# tviibh16m register map
Vendor: Infineon Technologies; Series: TVIIBH16M; File version: 1.0
CPU: CM7 r0p1, little endian, MPU, FPU, double-precision FPU, I-cache, D-cache, VTOR, ITCM, DTCM, 3 interrupt priority bits, 16 interrupts
Registers are 32-bit, read-write, reset 0x0 unless marked. A register's access mark holds for its fields unless they carry their own. Offsets are from the block's base; [hi:lo] are bit positions; {n}, {i} and the like mark numbered series.

## ETH0 (part 2 of 3) — Ethernet Interface
Base 0x40480000
Same registers: ETH1 0x40490000
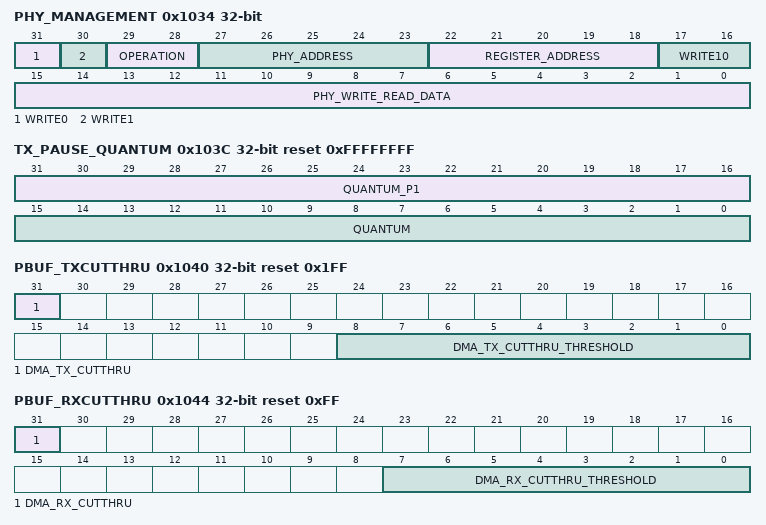
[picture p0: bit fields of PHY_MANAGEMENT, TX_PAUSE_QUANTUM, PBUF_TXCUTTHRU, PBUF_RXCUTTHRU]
0x1034 PHY_MANAGEMENT — The PHY maintenance register is implemented as a shift register. Writing to the register starts a shift operation which is signalled as complete when bit-2 is set in the network status register. It takes about 2000 pclk cycles to complete, when MDC is set for pclk divide by 32 in the network configuration register. An interrupt is generated upon completion. During this time, the MSB of the register is output on the MDIO pin and the LSB updated from the MDIO pin with each MDC cycle. This causes transmission of a PHY management frame on MDIO. See Section 22.2.4.5 of the IEEE 802.3 standard. Reading during the shift operation will return the current contents of the shift register. At the end of management operation, the bits will have shifted back to their original locations. For a read operation, the data bits will be updated with data read from the PHY. It is important to write the correct values to the register to ensure a valid PHY management frame is produced. The MDIO interface can read IEEE 802.3 clause 45 PHYs as well as clause 22 PHYs. To read clause 45 PHYs, bit 30 should be written with a 0 rather than a 1. For a description of MDC generation, see Network Configuration Register.
  [31] WRITE0 — Must be written with 0.
  [30] WRITE1 — Must be written to 1 for a valid Clause 22 frame and to 0 for a valid Clause 45 frame.
  [29:28] OPERATION — Operation. For a Clause 45 frame: 00 is an addr, 01 is a write, 10 is a post read increment, 11 is a read frame. For a Clause 22 frame: 10 is a read, 01 is a write.
  [27:23] PHY_ADDRESS
  [22:18] REGISTER_ADDRESS — Register address - specifies the register in the PHY to access.
  [17:16] WRITE10 — Must be written with 10.
  [15:0] PHY_WRITE_READ_DATA — For a write operation this is written with the data to be written to the PHY. After a read operation this contains the data read from the PHY.
0x1038 PAUSE_TIME ro — Received Pause Quantum Register
  [15:0] QUANTUM — Received pause quantum - stores the current value of the received pause quantum register which is decremented every 512 bit times.
0x103C TX_PAUSE_QUANTUM reset 0xFFFFFFFF — Transmit Pause Quantum Register
  [31:16] QUANTUM_P1 — Transmit pause quantum - written with the pause quantum value for pause frame transmission of priority 1.
  [15:0] QUANTUM — Transmit pause quantum - written with the pause quantum value for pause frame transmission.
0x1040 PBUF_TXCUTTHRU reset 0x1FF — Partial store and forward is only applicable when using the DMA configured in SRAM based packet buffer mode. It is also not available when using multi buffer frames. TX Partial Store and Forward
  [31] DMA_TX_CUTTHRU — Enable TX partial store and forward operation
  [8:0] DMA_TX_CUTTHRU_THRESHOLD — Watermark value. This value must be >= 0x9. The reset value depends on the value of the configuration option `gem_tx_pbuf_addr, which is defined in the verilog defs configuration file. The value chosen for the generation of the userguide was `gem_tx_pbuf_addr = 9
0x1044 PBUF_RXCUTTHRU reset 0xFF — RX Partial Store and Forward
  [31] DMA_RX_CUTTHRU — Enable RX partial store and forward operation
  [7:0] DMA_RX_CUTTHRU_THRESHOLD — Watermark value. The reset value depends on the value of the configuration option `gem_rx_pbuf_addr, which is defined in the verilog defs configuration file. The value chosen for the generation of the userguide was `gem_rx_pbuf_addr = 8.
0x1048 JUMBO_MAX_LENGTH reset 0x600 — Maximum Jumbo Frame Size.
  [13:0] JUMBO_MAX_LENGTH — Maximum Jumbo Frame Size - resets to the gem_jumbo_max_length define value.
0x104C EXTERNAL_FIFO_INTERFACE ro — Not presents.
  [31:0] REMOVED_31_0 — Write ignore, read 0
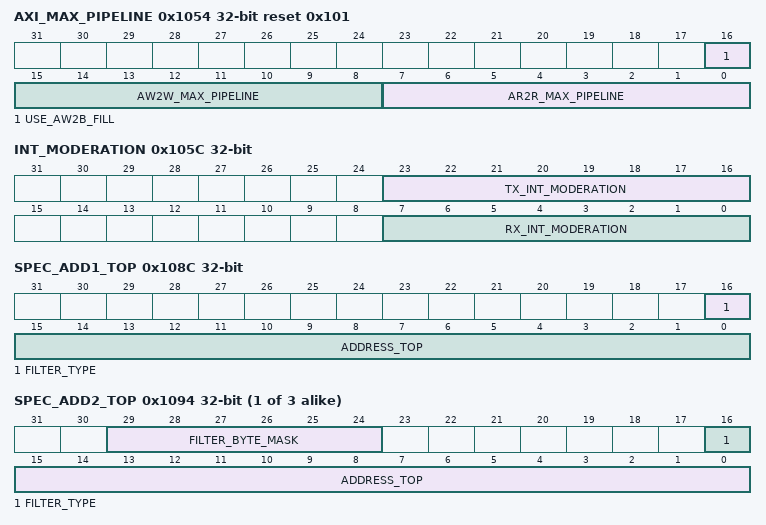
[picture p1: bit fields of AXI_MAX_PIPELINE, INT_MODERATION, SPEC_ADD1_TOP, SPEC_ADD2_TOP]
0x1054 AXI_MAX_PIPELINE reset 0x101 — Used to set the maximum amount of outstanding transactions on the AXI bus between AR / R channels and AW / W channels. Cannot be more than the depth of the configured AXI pipeline FIFO (defined in verilog defs.v)
  [16] USE_AW2B_FILL — For the write issuing capability as defined in bits 15:8 of this register, select whether the max number of transactions operates between the AW to W AXI channel or the AW to B channel. Set to 0 to operate between the AW and W channels. Set to 1 to operate between the AW and B channels.
  [15:8] AW2W_MAX_PIPELINE — Defines the maximum number of outstanding AXI write requests that can be issued by the DMA via the AW channel.
  [7:0] AR2R_MAX_PIPELINE — Defines the maximum number of outstanding AXI read requests that can be issued by the DMA via the AR channel.
0x1058 RSC_CONTROL ro — Not presents. Access to the register will return AHB error.
  [31:0] REMOVED_31_0 — Write ignore, read 0
0x105C INT_MODERATION — Used to moderate the number of transmit and receive complete interrupts issued. With interrupt moderation enabled receive and transmit interrupts are not generated immediately a frame is transmitted or received. Instead when a receive or transmit event occurs a timer is started and the interrupt is asserted after it times out. This limits the frequency with which the CPU receives interrupts. When interrupt moderation is enabled interrupt status bit one is always used for receive and bit 7 is always used for transmit even when priority queuing is enabled. With interrupt moderation 800ns periods are counted. GEM determines what constitutes an 800ns period by looking at the tbi (bit 11), gigabit bit (10) and speed (bit 0) bits in the network configuration register and counting tx_clk cycles. Bit 0 needs to be set to 1 for 100M operation.
  [23:16] TX_INT_MODERATION — Count of 800ns periods before bit 7 is set in the interrupt status register after a frame is transmitted. A non-zero value indicates transmit interrupt moderation will be performed.
  [7:0] RX_INT_MODERATION — Count of 800ns periods before bit 1 is set in the interrupt status register after a frame is received. A non-zero value indicates receive interrupt moderation will be performed.
0x1060 SYS_WAKE_TIME — Used to pause transmission after deassertion of tx_lpi_en. Each unit in this register corresponds to 64ns in gigabit mode, 320ns in 100M mode and 3200ns at 10M. After tx_lpi_en is deasserted transmission will pause for the set time.
  [15:0] SYS_WAKE_TIME — Count of 64ns, 320ns or 3200ns intervals before transmission starts after deassertion of tx_lpi_en (each interval is equivalent to eight tx_clk periods and so varies with data rate).
0x1080 HASH_BOTTOM — The unicast hash enable and the multicast hash enable bits in the network configuration register enable the reception of hash matched frames. Hash Register Bottom (31 to 0 bits)
  [31:0] ADDRESS_HASH_B — The first 32 bits of the hash address register.
0x1084 HASH_TOP — Hash Register Top (63 to 32 bits)
  [31:0] ADDRESS_HASH_T — The remaining 32 bits of the hash address register.
0x1088 SPEC_ADD1_BOTTOM — The addresses stored in the specific address registers are deactivated at reset or when their corresponding specific address register bottom is written. They are activated when specific address register top is written.
  [31:0] ADDRESS_ADD1_B — 'Least significant 32 bits of the destination address, that is bits 31:0. Bit zero indicates whether the address is multicast or unicast and corresponds to the least significant bit of the first byte received.'
0x108C SPEC_ADD1_TOP — Specific Address Top
  [16] FILTER_TYPE — This control bit selects whether this filter should be comparing the MAC source address or the MAC destination address of the received Ethernet frame. When set to zero, the filter is a destination address filter. When set to one, the filter is a source address filter. Specific address 1. The most significant bits of the destination address, that is bits 47:32.
  [15:0] ADDRESS_TOP — Specific address 1. The most significant bits of the destination/source address that is to be compared, that is bits 47:32.
{0x1080+8i} SPEC_ADD{i}_BOTTOM (i=2..4) — The addresses stored in the specific address registers are deactivated at reset or when their corresponding specific address register bottom is written. They are activated when specific address register top is written.
  [31:0] ADDRESS_BOTTOM — Least significant 32 bits of the destination address, that is bits 31:0. Bit zero indicates whether the address is multicast or unicast and corresponds to the least significant bit of the first byte received.
{0x1084+8i} SPEC_ADD{i}_TOP (i=2..4) — Specific Address Top
  [29:24] FILTER_BYTE_MASK — When high, the associated byte of the specific address will not be compared. Bit 24 controls whether the first byte received should be compared. Bit 29 controls whether the last byte received should be compared.
  [16] FILTER_TYPE — This control bit selects whether this filter should be comparing the MAC source address or the MAC destination address of the received Ethernet frame. When set to zero, the filter is a destination address filter. When set to one, the filter is a source address filter. Specific address 1. The most significant bits of the destination address, that is bits 47:32.
  [15:0] ADDRESS_TOP — Specific address 1. The most significant bits of the destination/source address that is to be compared, that is bits 47:32.
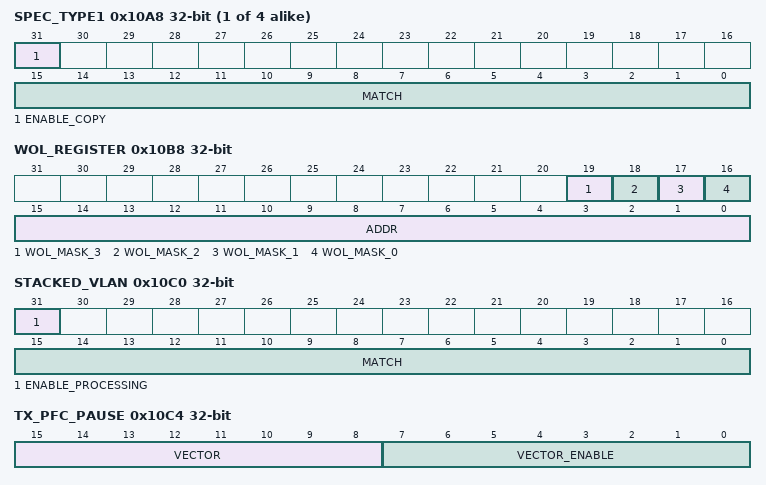
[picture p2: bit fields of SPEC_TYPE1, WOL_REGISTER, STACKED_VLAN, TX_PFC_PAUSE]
{0x10A4+4i} SPEC_TYPE{i} (i=1..4) — Type ID Match {i}
  [31] ENABLE_COPY — Enable copying of type ID match {i} matched frames.
  [15:0] MATCH — Type ID match {i}. For use in comparisons with received frames type ID/length field.
0x10B8 WOL_REGISTER — Wake on LAN Register. Presents in design, but feature is not supported.
  [19] WOL_MASK_3 — Wake on LAN multicast hash event enable. When set multicast hash events will cause the wol output to be asserted.
  [18] WOL_MASK_2 — Wake on LAN specific address register 1 event enable. When set specific address 1 events will cause the wol output to be asserted.
  [17] WOL_MASK_1 — Wake on LAN ARP request event enable. When set ARP request events will cause the wol output to be asserted.
  [16] WOL_MASK_0 — Wake on LAN magic packet event enable. When set magic packet events will cause the wol output to be asserted.
  [15:0] ADDR — Wake on LAN ARP request IP address. Written to define the least significant 16 bits of the target IP address that is matched to generate a Wake on LAN event. A value of zero will not generate an event, even if this is matched by the received frame.
0x10BC STRETCH_RATIO — IPG stretch register
  [15:0] IPG_STRETCH — IPG Stretch. Bits 7:0 are multiplied with the previously transmitted frame length (including preamble) bits 15:8 +1 divide the frame length. If the resulting number is greater than 96 and bit 28 is set in the network configuration register then the resulting number is used for the transmit inter-packet-gap. 1 is added to bits 15:8 to prevent a divide by zero.
0x10C0 STACKED_VLAN
  [31] ENABLE_PROCESSING — Enable stacked VLAN processing mode
  [15:0] MATCH — User defined VLAN_TYPE field. When Stacked VLAN is enabled, the first VLAN tag in a received frame will only be accepted if the VLAN type field is equal to this user defined VLAN_TYPE OR equal to the standard VLAN type (0x8100). Note that the second VLAN tag of a Stacked VLAN packet will only be matched correctly if its VLAN_TYPE field equals 0x8100.
0x10C4 TX_PFC_PAUSE — Transmit PFC Pause Register
  [15:8] VECTOR — Priority Vector Pause Size. If bit 17 of the network control register is written with a one then for each entry equal to zero in the Transmit PFC Pause Register[15:8], the PFC pause frame's pause quantum field associated with that entry will be taken from the transmit pause quantum register. For each entry equal to one in the Transmit PFC Pause Register [15:8], the pause quantum associated with that entry will be zero.
  [7:0] VECTOR_ENABLE — Priority Vector Enable. If bit 17 of the network control register is written with a one then the priority enable vector of the PFC priority based pause frame will be set equal to the value stored in this register [7:0].
0x10C8 MASK_ADD1_BOTTOM — Specific Address Mask 1 Bottom (31 to 0 bits)
  [31:0] ADDRESS_MASK_BOTTOM — Specific Address Mask. Setting a bit to one masks the corresponding bit in the specific address 1 register (31 to 0 bits)
0x10CC MASK_ADD1_TOP — Specific Address Mask 1 Top (47 to 32 bits)
  [15:0] ADDRESS_MASK_TOP — Specific Address Mask. Setting a bit to one masks the corresponding bit in the specific address 1 register (47 to 32 bits).
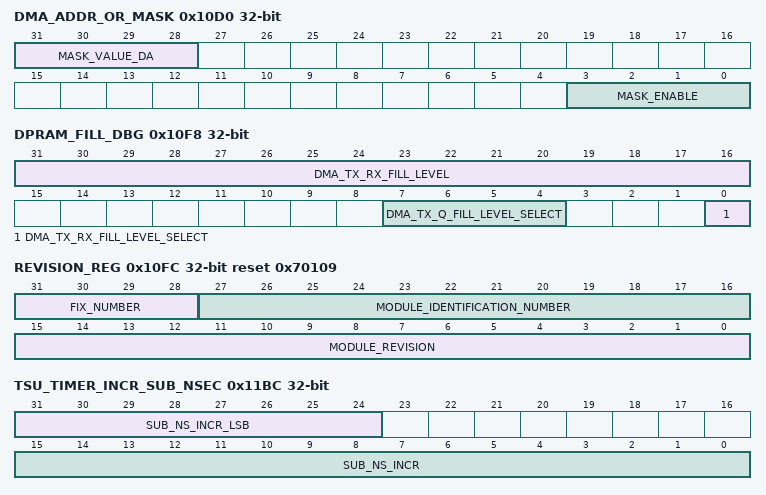
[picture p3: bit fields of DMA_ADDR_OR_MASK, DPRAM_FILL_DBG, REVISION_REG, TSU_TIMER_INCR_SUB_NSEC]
0x10D0 DMA_ADDR_OR_MASK — Receive DMA Data Buffer Address Mask
  [31:28] MASK_VALUE_DA — Data Buffer Address Mask Value. Values used to force bits 31:28 of the receive data buffer AHB address to a particular value when the associated enable bits stored in this register [3:0] are set. Any changes to this register will be ignored while the DMA is currently processing a receive packet. It will only affect the next full packet to be written to external system memory.
  [3:0] MASK_ENABLE — Data Buffer Address Mask Enable. These bits are associated directly with bits[31:28].When bit 0 is set, the AXI/AHB address bit 28 used for accessing the receive data buffers will be forced to the value stored in bit 28 of this register. When bit 1 is set, the AXI/AHB address bit 29 used for accessing the receive data buffers will be forced to the value stored in bit 29 of this register. When bit 2 is set, the AXI/AHB address bit 30 used for accessing the receive data buffers will be forced to the value stored in bit 30 of this register. When bit 3 is set, the AXI/AHB address bit 31 used for accessing the receive data buffers will be forced to the value stored in bit 31 of this register. When these bits are clear, the associated value stored in bits 31:28 have no effect on the AXI/AHB address used for receive data buffer accesses. Any changes to this register will be ignored while the DMA is currently processing a receive packet. It will only affect the next full packet to be written to external memory.
0x10D4 RX_PTP_UNICAST — PTP RX unicast IP destination address
  [31:0] ADDRESS_UNICAST — Unicast IP destination address. Used for detection of PTP frames on receive path.
0x10D8 TX_PTP_UNICAST — PTP TX unicast IP destination address
  [31:0] ADDRESS_UNICAST — Unicast IP destination address. Used for detection of PTP frames on transmit path.
0x10DC TSU_NSEC_CMP — TSU timer comparison value nanoseconds
  [21:0] COMPARISON_NSEC — TSU timer comparison value (ns). Value is compared to the bits[45:24] of the TSU timer count value (upper 22 bits of nanosecond value).
0x10E0 TSU_SEC_CMP — TSU timer comparison value seconds (31 to 0 bits)
  [31:0] COMPARISON_SEC — TSU timer comparison value (s). Value is compared to seconds value bits [31:0] of the TSU timer count value.
0x10E4 TSU_MSB_SEC_CMP — TSU timer comparison value seconds (47 to 32 bits)
  [15:0] COMPARISON_MSB_SEC — TSU timer comparison value (s). Value is compared to the top 16 bits (most significant 16-bits {47:32] of seconds value) of the TSU timer count value.
0x10E8 TSU_PTP_TX_MSB_SEC ro — PTP Event Frame Transmitted Seconds Register (47 to 32 bits)
  [15:0] TIMER_SECONDS — PTP Event Frame TX Seconds. The register is updated with the value that the 1588 timer seconds register held when the SFD of a PTP transmit primary event crosses the MII interface. The actual update occurs when the GEM recognizes the frame as a PTP sync or delay_req frame. An interrupt is issued when the register is updated.
0x10EC TSU_PTP_RX_MSB_SEC ro — PTP Event Frame Received Seconds Register (47 to 32 bits)
  [15:0] TIMER_SECONDS — PTP Event Frame TX Seconds. The register is updated with the value that the 1588 timer seconds register held when the SFD of a PTP receive primary event crosses the MII interface. The actual update occurs when the GEM recognizes the frame as a PTP sync or delay_req frame. An interrupt is issued when the register is updated.
0x10F0 TSU_PEER_TX_MSB_SEC ro — PTP Peer Event Frame Transmitted Seconds Register (47 to 32 bits)
  [15:0] TIMER_SECONDS — PTP Peer Event Frame TX Seconds. The register is updated with the value that the 1588 timer seconds register held when the SFD of a PTP transmit peer event crosses the MII interface. The actual update occurs when the GEM recognizes the frame as a PTP pdelay_req or pdelay_resp frame. An interrupt is issued when the register is updated.
0x10F4 TSU_PEER_RX_MSB_SEC ro — PTP Peer Event Frame Received Seconds Register (47 to 32 bits)
  [15:0] TIMER_SECONDS — PTP Peer Event Frame RX Seconds. The register is updated with the value that the 1588 timer seconds register held when the SFD of a PTP receive peer event crosses the MII interface. The actual update occurs when the GEM recognizes the frame as a PTP pdelay_req or pdelay_resp frame. An interrupt is issued when the register is updated.
0x10F8 DPRAM_FILL_DBG — The fill levels for the TX & RX packet buffers can be read using this register, including the fill level for each queue in the TX direction.
  [31:16] DMA_TX_RX_FILL_LEVEL ro — Fill Level - TX or RX packet buffer fill level, selected by the tx_q_fill_level_select and tx_rx_fill_level_select registers. Read this register to determine the fill level.
  [7:4] DMA_TX_Q_FILL_LEVEL_SELECT — TX queue fill level select - select what TX queue to report fill levels for.
  [0] DMA_TX_RX_FILL_LEVEL_SELECT — TX/RX Fill Level select - report the fill level for the TX or RX packet buffer.
0x10FC REVISION_REG ro reset 0x70109 — This register indicates a Cadence module identification number and module revision. The value of this register is read only as defined by `gem_revision_reg_value
  [31:28] FIX_NUMBER — Fix number - incremented for fix releases.
  [27:16] MODULE_IDENTIFICATION_NUMBER — Module identification number - for the GEM, this value is fixed.
  [15:0] MODULE_REVISION — Module revision - fixed value specific to the revision of the design which is incremented for each non-fix release of the IP.
0x1100 OCTETS_TXED_BOTTOM ro — Octets Transmitted lower bits (31 to 0 bits)
  [31:0] COUNT_BOTTOM read-clears — Transmitted octets in frame without errors [31:0]. The number of octets transmitted in valid frames of any type. This counter is 48-bits, and is read through two registers. This count does not include octets from automatically generated pause frames.
0x1104 OCTETS_TXED_TOP ro — Octets Transmitted higher bits (47 to 32 bits)
  [15:0] COUNT_TOP read-clears — Transmitted octets in frame without errors [47:32]. The number of octets transmitted in valid frames of any type. This counter is 48-bits, and is read through two registers. This count does not include octets from automatically generated pause frames.
0x1108 FRAMES_TXED_OK ro — Frames Transmitted
  [31:0] COUNT_OK read-clears — Frames transmitted without error. A 32 bit register counting the number of frames successfully transmitted, i.e. no under run and not too many retries. Excludes pause frames.
0x110C BROADCAST_TXED ro — Broadcast Frames Transmitted
  [31:0] COUNT_BROADCAST read-clears — Broadcast frames transmitted without error. A 32 bit register counting the number of broadcast frames successfully transmitted without error, i.e. no under run and not too many retries. Excludes pause frames.
0x1110 MULTICAST_TXED ro — Multicast Frames Transmitted
  [31:0] COUNT_MULTICAST read-clears — Multicast frames transmitted without error. A 32 bit register counting the number of multicast frames successfully transmitted without error, i.e. no under run and not too many retries. Excludes pause frames.
0x1114 PAUSE_FRAMES_TXED ro — Pause Frames Transmitted
  [15:0] COUNT_PAUSE read-clears — Transmitted pause frames - a 16 bit register counting the number of pause frames transmitted. Only pause frames triggered by the register interface or through the external pause pins are counted as pause frames. Pause frames received through the external FIFO interface are counted in the frames transmitted counter.
0x1118 FRAMES_TXED_64 ro — 64 Byte Frames Transmitted
  [31:0] COUNT_64 read-clears — 64 byte frames transmitted without error. A 32 bit register counting the number of 64 byte frames successfully transmitted without error, i.e. no under run and not too many retries. Excludes pause frames.
0x111C FRAMES_TXED_65 ro — 65 to 127 Byte Frames Transmitted
  [31:0] COUNT_65 read-clears — 65 to127 byte frames transmitted without error. A 32 bit register counting the number of 65 to127 byte frames successfully transmitted without error, i.e. no under run and not too many retries.
0x1120 FRAMES_TXED_128 ro — 128 to 255 Byte Frames Transmitted
  [31:0] COUNT_128 read-clears — 128 to 255 byte frames transmitted without error. A 32 bit register counting the number of 128 to 255 byte frames successfully transmitted without error, i.e. no under run and not too many retries.
0x1124 FRAMES_TXED_256 ro — 256 to 511 Byte Frames Transmitted
  [31:0] COUNT_256 read-clears — 256 to 511 byte frames transmitted without error. A 32 bit register counting the number of 256 to 511 byte frames successfully transmitted without error, i.e. no under run and not too many retries.
0x1128 FRAMES_TXED_512 ro — 512 to 1023 Byte Frames Transmitted
  [31:0] COUNT_512 read-clears — 512 to 1023 byte frames transmitted without error. A 32 bit register counting the number of 512 to 1023 byte frames successfully transmitted without error, i.e. no under run and not too many retries.
0x112C FRAMES_TXED_1024 ro — 1024 to 1518 Byte Frames Transmitted
  [31:0] COUNT_1024 read-clears — 1024 to 1518 byte frames transmitted without error. A 32 bit register counting the number of 1024 to 1518 byte frames successfully transmitted without error, i.e. no under run and not too many retries.
0x1130 FRAMES_TXED_1519 ro — Greater Than 1518 Byte Frames Transmitted
  [31:0] COUNT_1519 read-clears — Greater than 1518 byte frames transmitted without error. A 32 bit register counting the number of 1518 or above byte frames successfully transmitted without error, i.e. no under run and not too many retries.
0x1134 TX_UNDERRUNS ro — Transmit Under Runs
  [9:0] COUNT_UN read-clears — Transmit under runs - a 10 bit register counting the number of frames not transmitted due to a transmit under run. If this register is incremented then no other statistics register is incremented.
0x1138 SINGLE_COLLISIONS ro — Single Collision Frames. Presents in design but not support.
  [17:0] COUNT14 read-clears — Single collision frames - an 18 bit register counting the number of frames experiencing a single collision before being successfully transmitted, i.e. no under run.
0x113C MULTIPLE_COLLISIONS ro — Multiple Collision Frames. Presents in design but not support.
  [17:0] COUNT15 read-clears — Multiple collision frames - an 18 bit register counting the number of frames experiencing between two and fifteen collisions prior to being successfully transmitted, i.e. no under run and not too many retries.
0x1140 EXCESSIVE_COLLISIONS ro — Excessive Collisions. Presents in design but not support.
  [9:0] COUNT16 read-clears — Excessive collisions - a 10 bit register counting the number of frames that failed to be transmitted because they experienced 16 collisions.
0x1144 LATE_COLLISIONS ro — Late Collisions. Presents in design but not support.
  [9:0] COUNT17 read-clears — Late collisions - a 10 bit register counting the number of late collision occurring after the slot time (512 bits) has expired. In 10/100 mode, late collisions are counted twice i.e. both as a collision and a late collision. In gigabit mode, a late collision causes the transmission to be aborted, thus the single and multi collision registers are not updated.
0x1148 DEFERRED_FRAMES ro — Deferred Transmission Frames. Presents in design but not support.
  [17:0] COUNT18 read-clears — Deferred transmission frames - an 18 bit register counting the number of frames experiencing deferral due to carrier sense being active on their first attempt at transmission. Frames involved in any collision are not counted nor are frames that experienced a transmit under run.
0x114C CRS_ERRORS ro — Carrier Sense Errors. Presents in design but not support.
  [9:0] COUNT19 read-clears — Carrier sense errors - a 10 bit register counting the number of frames transmitted where carrier sense was not seen during transmission or where carrier sense was deasserted after being asserted in a transmit frame without collision (no under run). Only incremented in half duplex mode. The only effect of a carrier sense error is to increment this register. The behaviour of the other statistics registers is unaffected by the detection of a carrier sense error.
0x1150 OCTETS_RXED_BOTTOM ro — Octets Received (31 to 0 bits)
  [31:0] COUNT_BOTTOM read-clears — Received octets in frame without errors [31:0]. The number of octets received in valid frames of any type. This counter is 48-bits and is read through two registers. This count does not include octets from pause frames, and is only incremented if the frame is successfully filtered.
0x1154 OCTETS_RXED_TOP ro — Octets Received (47 to 32 bits)
  [15:0] COUNT_TOP read-clears — Received octets in frame without errors [47:32]. The number of octets received in valid frames of any type. This counter is 48-bits and is read through two registers. This count does not include octets from pause frames, and is only incremented if the frame is successfully filtered.
0x1158 FRAMES_RXED_OK ro — Frames Received
  [31:0] COUNT_OK read-clears — Frames received without error. A 32 bit register counting the number of frames successfully received. Excludes pause frames, and is only incremented if the frame is successfully filtered.
0x115C BROADCAST_RXED ro — Broadcast Frames Received
  [31:0] COUNT_BROADCAST read-clears — Broadcast frames received without error. A 32 bit register counting the number of broadcast frames successfully received without error. Excludes pause frames, and is only incremented if the frame is successfully filtered.
0x1160 MULTICAST_RXED ro — Multicast Frames Received
  [31:0] COUNT_MULTICAST read-clears — Multicast frames received without error. A 32 bit register counting the number of multicast frames successfully received without error. Excludes pause frames, and is only incremented if the frame is successfully filtered.
0x1164 PAUSE_FRAMES_RXED ro — Pause Frames Received
  [15:0] COUNT_PAUSE read-clears — Received pause frames - a 16 bit register counting the number of pause frames received without error.
0x1168 FRAMES_RXED_64 ro — 64 Byte Frames Received
  [31:0] COUNT_64 read-clears — 64 byte frames received without error. A 32 bit register counting the number of 64 byte frames successfully received without error. Excludes pause frames, and is only incremented if the frame is successfully filtered.
0x116C FRAMES_RXED_65 ro — 65 to 127 Byte Frames Received
  [31:0] COUNT_65 read-clears — 65 to 127 byte frames received without error. A 32 bit register counting the number of 65 to 127 byte frames successfully received without error. Excludes pause frames, and is only incremented if the frame is successfully filtered.
0x1170 FRAMES_RXED_128 ro — 128 to 255 Byte Frames Received
  [31:0] COUNT_128 read-clears — 128 to 255 byte frames received without error. A 32 bit register counting the number of 128 to 255 byte frames successfully received without error. Excludes pause frames, and is only incremented if the frame is successfully filtered.
0x1174 FRAMES_RXED_256 ro — 256 to 511 Byte Frames Received
  [31:0] COUNT_256 read-clears — 256 to 511 byte frames received without error. A 32 bit register counting the number of 256 to 511 byte frames successfully transmitted without error. Excludes pause frames, and is only incremented if the frame is successfully filtered.
0x1178 FRAMES_RXED_512 ro — 512 to 1023 Byte Frames Received
  [31:0] COUNT_512 read-clears — 512 to 1023 byte frames received without error. A 32 bit register counting the number of 512 to 1023 byte frames successfully received without error. Excludes pause frames, and is only incremented if the frame is successfully filtered.
0x117C FRAMES_RXED_1024 ro — 1024 to 1518 Byte Frames Received
  [31:0] COUNT_1024 read-clears — 1024 to 1518 byte frames received without error. A 32 bit register counting the number of 1024 to 1518 byte frames successfully received without error. Excludes pause frames, and is only incremented if the frame is successfully filtered.
0x1180 FRAMES_RXED_1519 ro — 1519 to maximum Byte Frames Received
  [31:0] COUNT_1519 read-clears — 1519 to maximum byte frames received without error. A 32 bit register counting the number of 1519 byte or above frames successfully received without error. Maximum frame size is determined by the network configuration register bit 8 (1536 maximum frame size) or bit 3 (jumbo frame size). Excludes pause frames, and is only incremented if the frame is successfully filtered.
0x1184 UNDERSIZE_FRAMES ro — Undersized Frames Received
  [9:0] COUNT_UNDERSIZE read-clears — Undersize frames received - a 10 bit register counting the number of frames received less than 64 bytes in length (10/100 mode or gigabit mode, full duplex) that do not have either a CRC error or an alignment error. In gigabit mode, half duplex, this register counts either frames not conforming to the minimum slot time of 512 bytes or frames not conforming to the minimum frame size once bursting is active.
0x1188 EXCESSIVE_RX_LENGTH ro — Oversize Frames Received
  [9:0] COUNT_OVERSIZE read-clears — Oversize frames received - a 10 bit register counting the number of frames received exceeding 1518 bytes (1536 bytes if bit 8 is set in network configuration register, 10,240 bytes if bit 3 is set in the network configuration register) in length but do not have either a CRC error, an alignment error nor a receive symbol error.
0x118C RX_JABBERS ro — Jabbers Received
  [9:0] COUNT_JABBERS read-clears — Jabbers received - a 10 bit register counting the number of frames received exceeding 1518 bytes (1536 if bit 8 set in network configuration register, 10,240 bytes if bit 3 is set in the network configuration register) in length and have either a CRC error, an alignment error or a receive symbol error.
0x1190 FCS_ERRORS ro — Frame Check Sequence Errors
  [9:0] COUNT_FCS_ERR read-clears — Frame check sequence errors - a 10 bit register counting frames that are an integral number of bytes, have bad CRC and are between 64 and 1518 bytes in length (1536 if bit 8 set in network configuration register, 10,240 bytes if bit 3 is set in the network configuration register). This register is also incremented if a symbol error is detected and the frame is of valid length and has an integral number of bytes. This register is incremented for a frame with bad FCS, regardless of whether it is copied to memory due to ignore FCS mode being enabled in bit 26 of the network configuration register.
0x1194 RX_LENGTH_ERRORS ro — Length Field Frame Errors
  [9:0] COUNT_LENGTH_ERR read-clears — Length field frame errors - this 10-bit register counts the number of frames received that have a measured length shorter than that extracted from the length field (bytes 13 and 14). This condition is only counted if the value of the length field is less than 0x0600, the frame is not of excessive length and checking is enabled through bit 16 of the network configuration register.
0x1198 RX_SYMBOL_ERRORS ro — Receive Symbol Errors
  [9:0] COUNT_SYMBOL_ERR read-clears — Receive symbol errors - a 10-bit register counting the number of frames that had rx_er asserted during reception. For 10/100 mode symbol errors are counted regardless of frame length checks. For gigabit mode the frame must satisfy slot time requirements in order to count a symbol error. Additionally, in gigabit half duplex mode, carrier extension errors are also recorded. Receive symbol errors will also be counted as an FCS or alignment error if the frame is between 64 and 1518 bytes (1536 bytes if bit 8 is set in the network configuration register, 10240 bytes if bit 3 is set in the network configuration register). If the frame is larger it will be recorded as a jabber error.
0x119C ALIGNMENT_ERRORS ro
  [9:0] COUNT_ALIGNMENT_ERROR read-clears — Alignment errors - a 10 bit register counting frames that are not an integral number of bytes long and have bad CRC when their length is truncated to an integral number of bytes and are between 64 and 1518 bytes in length (1536 if bit 8 set in network configuration register, 10,240 bytes if bit 3 is set in the network configuration register). This register is also incremented if a symbol error is detected and the frame is of valid length and does not have an integral number of bytes.
0x11A0 RX_RESOURCE_ERRORS ro — Receive Resource Errors
  [17:0] COUNT_RESOURCE_ERR read-clears — Receive resource errors - an 18 bit register counting the number of frames that were successfully received by the MAC (correct address matched frame and adequate slot time) but could not be copied to memory because no receive buffer was available. This occurs when the GEM reads a buffer descriptor with its ownership (or used) bit set.
0x11A4 RX_OVERRUNS ro — Receive Overruns
  [9:0] COUNT_OVERRUN read-clears — Receive overruns - a 10 bit register counting the number of frames that are address recognized but were not copied to memory due to a receive overrun.
0x11A8 RX_IP_CK_ERRORS ro — IP Header Checksum Errors
  [7:0] COUNT_IPCK_ERR read-clears — IP header checksum errors - an 8-bit register counting the number of frames discarded due to an incorrect IP header checksum, but are between 64 and 1518 bytes (1536 bytes if bit 8 is set in the network configuration register or 10240 bytes if bit 3 is in the network configuration register) and do not have a CRC error, an alignment error, nor a symbol error.
0x11AC RX_TCP_CK_ERRORS ro — TCP Checksum Errors
  [7:0] COUNT_TCPCK_ERR read-clears — TCP checksum errors - an 8-bit register counting the number of frames discarded due to an incorrect TCP checksum, but are between 64 and 1518 bytes (1536 bytes if bit 8 is set in the network configuration register or 10240 bytes if bit 3 is in the network configuration register) and do not have a CRC error, an alignment error, nor a symbol error.
0x11B0 RX_UDP_CK_ERRORS ro — UDP Checksum Errors
  [7:0] COUNT_UDPCK_ERR read-clears — UDP checksum errors - an 8-bit register counting the number of frames discarded due to an incorrect UDP checksum, but are between 64 and 1518 bytes (1536 bytes if bit 8 is set in the network configuration register or 10240 bytes if bit 3 is in the network configuration register) and do not have a CRC error, an alignment error, nor a symbol error.
0x11B4 AUTO_FLUSHED_PKTS ro — Receive DMA Flushed Packets
  [15:0] COUNT_FLUSHED read-clears — Flushed RX packets counter. A 16 bit register counting the number of frames that have been flushed from the receive SRAM based packet buffer due to one of the following reasons .1. When partial store and forward mode is enabled or bit 24 of the DMA configuration register is enabled, a packet is received while there is no AMBA (AXI/AHB) resource. 2. When partial store and forward mode is enabled and an AMBA (AXI/AHB) error is encountered while writing the packet data to external memory. When bit 18 of the network control register(software action to flush a packet from the head of the PBUF queue) is pulsed and the GEM DMA is not currently busy.
0x11BC TSU_TIMER_INCR_SUB_NSEC — 1588 Timer Increment Register sub nsec
  [31:24] SUB_NS_INCR_LSB — These are the least significant bits [7:0] of the sub-ns value by which the 1588 timer will be incremented each clock cycle.
  [15:0] SUB_NS_INCR — These are the most significant bits [23:8] of the sub-ns value by which the 1588 timer will be incremented each clock cycle. 24 bits of sub nanosecond precision gives resolution of approximately 5.86E-17 seconds (16 bits gives 15.2 femtoseconds).
0x11C0 TSU_TIMER_MSB_SEC — 1588 Timer Seconds Register (47 to 32 bits)
  [15:0] TIMER_MSB_SEC — TSU timer value (s). Most significant 16 bits of seconds timer count. The register is writeable. The 48-bit counter increments by one when the 1588 nanoseconds counter counts to one second. It may also be incremented or decremented when the timer adjust register is written (if decremented from zero the 48-bit combined count would roll back to 0xFFFFFFFFFFFF). Note: The value of this register is used only when the lower 32 bit register is written to. This is to ensure a single update of the 48 bit seconds value
0x11C4 TSU_STROBE_MSB_SEC ro — 1588 Timer Sync Strobe Seconds Register (47 to 32 bits)
  [15:0] STROBE_MSB_SEC — 1588 Timer Sync Strobe Seconds. The most significant 16-bit value of the Timer Seconds register captured when gem_tsu_ms and gem_tsu_inc_ctrl are zero.
0x11C8 TSU_STROBE_SEC ro — 1588 Timer Sync Strobe Seconds Register (31 to 0 bits)
  [31:0] STROBE_SEC — 1588 Timer Sync Strobe Seconds. The lowest significant 32-bit value of the Timer Seconds register captured when gem_tsu_ms and gem_tsu_inc_ctrl are zero.
0x11CC TSU_STROBE_NSEC ro — 1588 Timer Sync Strobe Nanoseconds Register
  [29:0] STROBE_NSEC — 1588 Timer Sync Strobe Nanoseconds. The value of the Timer Nanoseconds register captured when gem_tsu_ms and gem_tsu_inc_ctrl are zero.
0x11D0 TSU_TIMER_SEC — 1588 Timer Seconds Register (31 to 0 bits)
  [31:0] TIMER_SEC — 1588 Timer Seconds Register. TSU timer value (s). Least significant 32 bits of seconds timer count. This register is writeable. The 48-bit counter increments by one when the 1588 nanoseconds counter counts to one second. It may also be incremented or decremented when the timer adjust register is written (if decremented from zero the 48-bit combined count would roll back to 0xFFFFFFFFFFFF).
0x11D4 TSU_TIMER_NSEC — 1588 Timer Nanoseconds Register
  [29:0] TIMER_NSEC — Timer count in nanoseconds. This register is writeable. It can also be adjusted by writes to the 1588 timer adjust register. It increments by the value of the 1588 timer increment register each clock cycle (if this register is close to zero and a write to the timer adjust register causes a decrement the seconds register will be decremented if necessary and the nanoseconds register will roll back to 9999999xx(decimal)).
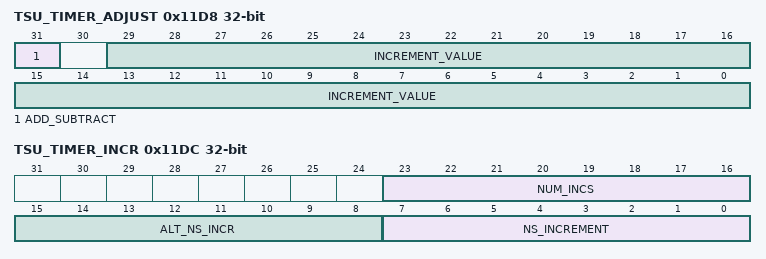
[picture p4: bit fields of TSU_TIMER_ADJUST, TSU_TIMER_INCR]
0x11D8 TSU_TIMER_ADJUST wo — This register is used to adjust the value of the timer in the TSU. It allows an integral number of nanoseconds to be added or subtracted from the timer in a one-off operation. This register returns all zeroes when read.
  [31] ADD_SUBTRACT — Write as one to subtract from the 1588 timer. Write as zero to add to it.
  [29:0] INCREMENT_VALUE — Timer increment value. The number of nanoseconds to increment or decrement the 1588 timer nanoseconds register. If necessary the 1588 seconds register will be incremented or decremented.
0x11DC TSU_TIMER_INCR — 1588 Timer Increment Register
  [23:16] NUM_INCS — Number of incs before alt inc. The number of increments after which the alternative increment is used.
  [15:8] ALT_NS_INCR — Alternative nanoseconds count. Alternative count of nanoseconds by which the 1588 timer nanoseconds register will be incremented each clock cycle.
  [7:0] NS_INCREMENT — A count of nanoseconds by which the 1588 timer nanoseconds register will be incremented each clock cycle. These are the most significant 8 bits of the 32 bit timer_increment counter. The tsu_timer_incr_sub_nsec register holds the least significant 24 bits of the increment.
0x11E0 TSU_PTP_TX_SEC ro — PTP Event Frame Transmitted Seconds Register (31 to 0 bits)
  [31:0] TIMER_PTP_SEC — PTP Event Frame Transmitted Seconds. The register is updated with the value that the 1588 timer seconds register held when the SFD of a PTP transmit primary event crosses the MII interface. The actual update occurs when the GEM recognizes the frame as a PTP sync or delay_req frame. An interrupt is issued when the register is updated.
0x11E4 TSU_PTP_TX_NSEC ro — PTP Event Frame Transmitted Nanoseconds Register
  [29:0] TIMER_PTP_NSEC — PTP Event Frame Transmitted Nanoseconds. The register is updated with the value that the 1588 timer nanoseconds register held when the SFD of a PTP transmit primary event crosses the MII interface. The actual update occurs when the GEM recognizes the frame as a PTP sync or delay_req frame. An interrupt is issued when the register is updated.
0x11E8 TSU_PTP_RX_SEC ro — PTP Event Frame Received Seconds Register (31 to 0 bits)
  [31:0] TIMER_PTP_SEC — PTP Event Frame Received Seconds. The register is updated with the value that the 1588 timer seconds register held when the SFD of a PTP receive primary event crosses the MII interface. The actual update occurs when the GEM recognizes the frame as a PTP sync or delay_req frame. An interrupt is issued when the register is updated.
0x11EC TSU_PTP_RX_NSEC ro — PTP Event Frame Received Nanoseconds Register
  [29:0] TIMER_PTP_NSEC — PTP Event Frame Received Nanoseconds. The register is updated with the value that the 1588 timer nanoseconds register held when the SFD of a PTP receive primary event crosses the MII interface. The actual update occurs when the GEM recognizes the frame as a PTP sync or delay_req frame. An interrupt is issued when the register is updated.
0x11F0 TSU_PEER_TX_SEC ro — PTP Peer Event Frame Transmitted Seconds Register (31 to 0 bits)
  [31:0] TIMER_PEER_SEC — PTP Peer Event Frame Received Seconds. The register is updated with the value that the 1588 timer seconds register held when the SFD of a PTP transmit peer event crosses the MII interface. The actual update occurs when the GEM recognizes the frame as a PTP pdelay_req or pdelay_resp frame. An interrupt is issued when the register is updated.
0x11F4 TSU_PEER_TX_NSEC ro — PTP Peer Event Frame Transmitted Nanoseconds Register
  [29:0] TIMER_PEER_NSEC — PTP Peer Event Frame Transmitted Nanoseconds. The register is updated with the value that the 1588 timer nanoseconds register held when the SFD of a PTP transmit peer event crosses the MII interface. The actual update occurs when the GEM recognizes the frame as a PTP pdelay_req or pdelay_resp frame. An interrupt is issued when the register is updated.
